# ATmega32C1 device description
Architecture: AVR8; Family: megaAVR
Registers are 8-bit, access not given, no defined reset value unless marked. A register's access mark holds for its fields unless they carry their own. Offsets are from the block's base; [hi:lo] are bit positions; {n}, {i} and the like mark numbered series.

## TC1 (TC16 module) — Timer/Counter, 16-bit
Instances: TC1 0x00
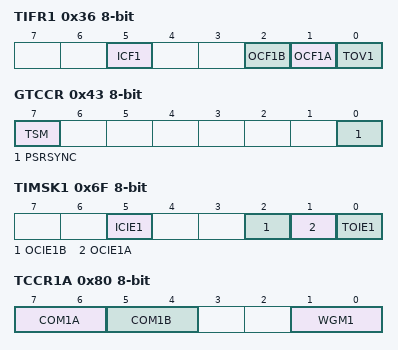
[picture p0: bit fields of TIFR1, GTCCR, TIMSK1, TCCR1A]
0x36 TIFR1 — Timer/Counter Interrupt Flag register
  [5] ICF1 — Input Capture Flag 1
  [2] OCF1B — Output Compare Flag 1B
  [1] OCF1A — Output Compare Flag 1A
  [0] TOV1 — Timer/Counter1 Overflow Flag
0x43 GTCCR — General Timer/Counter Control Register
  [7] TSM — Timer/Counter Synchronization Mode
  [0] PSRSYNC — Prescaler Reset Timer/Counter1 and Timer/Counter0
0x6F TIMSK1 — Timer/Counter Interrupt Mask Register
  [5] ICIE1 — Timer/Counter1 Input Capture Interrupt Enable
  [2] OCIE1B — Timer/Counter1 Output CompareB Match Interrupt Enable
  [1] OCIE1A — Timer/Counter1 Output CompareA Match Interrupt Enable
  [0] TOIE1 — Timer/Counter1 Overflow Interrupt Enable
0x80 TCCR1A — Timer/Counter1 Control Register A
  [7:6] COM1A — Compare Output Mode 1A, bits
  [5:4] COM1B — Compare Output Mode 1B, bits
  [1:0] WGM1 — Waveform Generation Mode
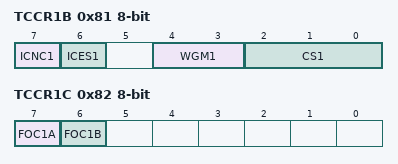
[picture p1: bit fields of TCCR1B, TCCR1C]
0x81 TCCR1B — Timer/Counter1 Control Register B
  [7] ICNC1 — Input Capture 1 Noise Canceler
  [6] ICES1 — Input Capture 1 Edge Select
  [4:3] WGM1 (bit 2 of the value upward) — Waveform Generation Mode
  [2:0] CS1 — Prescaler source of Timer/Counter 1
    0=NO_CLOCK_SOURCE_STOPPED; 1=RUNNING_NO_PRESCALING; 2=RUNNING_CLK_8; 3=RUNNING_CLK_64; 4=RUNNING_CLK_256; 5=RUNNING_CLK_1024; 6=RUNNING_EXTCLK_TN_FALLING_EDGE; 7=RUNNING_EXTCLK_TN_RISING_EDGE
0x82 TCCR1C — Timer/Counter1 Control Register C
  [7] FOC1A, [6] FOC1B
0x84 TCNT1 16-bit — Timer/Counter1 Bytes
  [15:0] TCNT1 — Timer/Counter1 bits
0x86 ICR1 16-bit — Timer/Counter1 Input Capture Register Bytes
  [15:0] ICR1 — Timer/Counter1 Input Capture bits
0x88 OCR1A 16-bit — Timer/Counter1 Output Compare Register Bytes
  [15:0] OCR1A — Timer/Counter1 Output Compare bits
0x8A OCR1B 16-bit — Timer/Counter1 Output Compare Register Bytes
  [15:0] OCR1B — Timer/Counter1 Output Compare bits

## ADC — Analog-to-Digital Converter
Instances: ADC 0x00
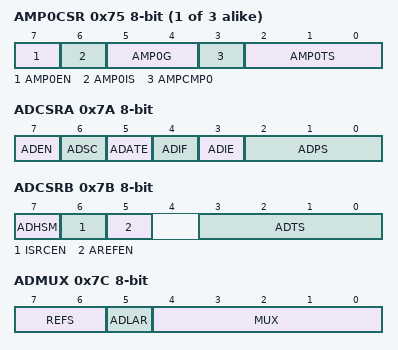
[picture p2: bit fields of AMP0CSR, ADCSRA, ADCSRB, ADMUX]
{0x75+i} AMP{i}CSR (i=0..2)
  [7] AMP{i}EN
  [6] AMP{i}IS
  [5:4] AMP{i}G
  [3] AMPCMP{i} — Amplifier {i} - Comparator {i} Connection
  [2:0] AMP{i}TS
0x78 ADC 16-bit — ADC Data Register Bytes
  [9:0] ADC — ADC Data bits
0x7A ADCSRA — The ADC Control and Status register
  [7] ADEN — ADC Enable
  [6] ADSC — ADC Start Conversion
  [5] ADATE — ADC Auto Trigger Enable
  [4] ADIF — ADC Interrupt Flag
  [3] ADIE — ADC Interrupt Enable
  [2:0] ADPS — ADC Prescaler Select Bits
0x7B ADCSRB — ADC Control and Status Register B
  [7] ADHSM — ADC High Speed Mode
  [6] ISRCEN — Current Source Enable
  [5] AREFEN — Analog Reference pin Enable
  [3:0] ADTS — ADC Auto Trigger Sources
    0=FREE_RUNNING_MODE; 1=ANALOG_COMPARATOR; 2=EXTERNAL_INTERRUPT_REQUEST_0; 3=TIMER_COUNTER0_COMPARE_MATCH_A; 4=TIMER_COUNTER0_OVERFLOW; 5=TIMER_COUNTER1_COMPARE_MATCH_B; 6=TIMER_COUNTER1_OVERFLOW; 7=TIMER_COUNTER1_CAPTURE_EVENT; 8=PSC0ASY_EVENT; 9=PSC1ASY_EVENT; 10=PSC2ASY_EVENT; 11=ANALOG_COMPARATOR_1; 12=ANALOG_COMPARATOR_2
0x7C ADMUX — The ADC multiplexer Selection Register
  [7:6] REFS — Reference Selection Bits
    0=AREF_INTERNAL_VREF_TURNED_OFF; 1=AVCC_REFERENCE; 3=INTERNAL_2_56V_VOLTAGE_REFERENCE
  [5] ADLAR — Left Adjust Result
  [4:0] MUX — Analog Channel and Gain Selection Bits
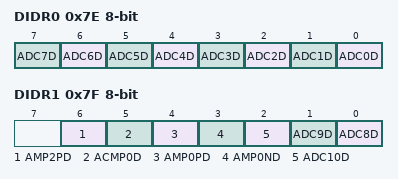
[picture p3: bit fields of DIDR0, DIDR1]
0x7E DIDR0 — Digital Input Disable Register 0
  [n] ADC{n}D (n=0..7) — ADC{n} Digital input Disable
0x7F DIDR1 — Digital Input Disable Register 0
  [6] AMP2PD — AMP2P Pin Digital input Disable
  [5] ACMP0D — ACMP0 Pin Digital input Disable
  [4] AMP0PD — AMP0P Pin Digital input Disable
  [3] AMP0ND — AMP0N Pin Digital input Disable
  [2] ADC10D — ADC10 Pin Digital input Disable
  [1] ADC9D — ADC9 Pin Digital input Disable
  [0] ADC8D — ADC8 Pin Digital input Disable
Value list ANALOG_ADC_MUXPOS: {v}=ADC{v} (ADC input pin {v}) (v=0..10); 11=TEMPSENSE (Temperature sensor); 12=VCC4 (Internal VCC / 4); 13=ISRC (Current source); 14=AMP0 (Analog Differential Amplifier 0); 15=AMP1 (Analog Differential Amplifier 1); 16=AMP2 (Analog Differential Amplifier 2); 17=BNDGAP (Bandgap); 18=GND (0V (GND))
